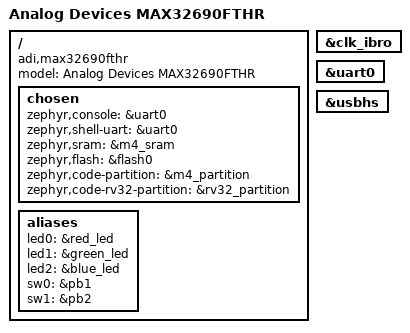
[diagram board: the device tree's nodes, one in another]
/*
 * Copyright (c) 2023-2024 Analog Devices, Inc.
 *
 * SPDX-License-Identifier: Apache-2.0
 */

/dts-v1/;

#include <adi/max32/max32690-m4.dtsi>
#include "max32690fthr.dtsi"

/ {
	model = "Analog Devices MAX32690FTHR";
	compatible = "adi,max32690fthr";

	chosen {
		zephyr,console = &uart0;
		zephyr,shell-uart = &uart0;
		zephyr,sram = &m4_sram;
		zephyr,flash = &flash0;
		zephyr,code-partition = &m4_partition;
		zephyr,code-rv32-partition = &rv32_partition;
	};

	aliases {
		led0 = &red_led;
		led1 = &green_led;
		led2 = &blue_led;
		sw0 = &pb1;
		sw1 = &pb2;
	};
};

&clk_ibro {
	status = "okay";
};

&uart0 {
	status = "okay";
};

zephyr_udc0: &usbhs {
	status = "okay";
};
